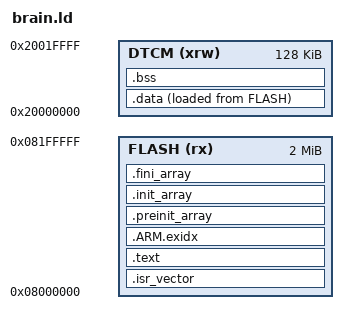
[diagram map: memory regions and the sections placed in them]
/* STM32H753ZI: standalone brain application at the start of flash.
 *
 * Placement (see NOTES.md):
 *   flash  : vectors, code, const data including the CSR weights
 *   DTCM   : .data, .bss, stack. The neuron state (r, next) lives in .bss, so it is in the
 *            zero-wait-state tightly coupled memory. No heap: the firmware never allocates.
 */
ENTRY(Reset_Handler)

MEMORY
{
  FLASH (rx)  : ORIGIN = 0x08000000, LENGTH = 2048K
  DTCM  (xrw) : ORIGIN = 0x20000000, LENGTH = 128K
}

_estack = ORIGIN(DTCM) + LENGTH(DTCM);

SECTIONS
{
  .isr_vector : ALIGN(1024)
  {
    KEEP(*(.isr_vector))
    . = ALIGN(4);
  } >FLASH

  .text :
  {
    *(.text*)
    *(.rodata*)
    KEEP(*(.init))
    KEEP(*(.fini))
    . = ALIGN(4);
  } >FLASH

  .ARM.exidx : { *(.ARM.exidx*) } >FLASH

  .preinit_array : { PROVIDE_HIDDEN(__preinit_array_start = .); KEEP(*(.preinit_array*)) PROVIDE_HIDDEN(__preinit_array_end = .); } >FLASH
  .init_array    : { PROVIDE_HIDDEN(__init_array_start = .); KEEP(*(SORT(.init_array.*))) KEEP(*(.init_array*)) PROVIDE_HIDDEN(__init_array_end = .); } >FLASH
  .fini_array    : { PROVIDE_HIDDEN(__fini_array_start = .); KEEP(*(SORT(.fini_array.*))) KEEP(*(.fini_array*)) PROVIDE_HIDDEN(__fini_array_end = .); } >FLASH

  _sidata = LOADADDR(.data);

  .data :
  {
    _sdata = .;
    *(.data*)
    . = ALIGN(4);
    _edata = .;
  } >DTCM AT >FLASH

  .bss (NOLOAD) :
  {
    _sbss = .;
    __bss_start__ = _sbss;
    *(.bss*)
    *(COMMON)
    . = ALIGN(4);
    _ebss = .;
    __bss_end__ = _ebss;
  } >DTCM

  /* Fail the link if the stack would have less than 8 KB left. */
  ASSERT(_ebss + 8K <= _estack, "DTCM too small: less than 8 KB left for the stack")

  /DISCARD/ : { *(.ARM.attributes) }
}
